AUTOSAR XML (schema 00049)
package /ComponentTypes
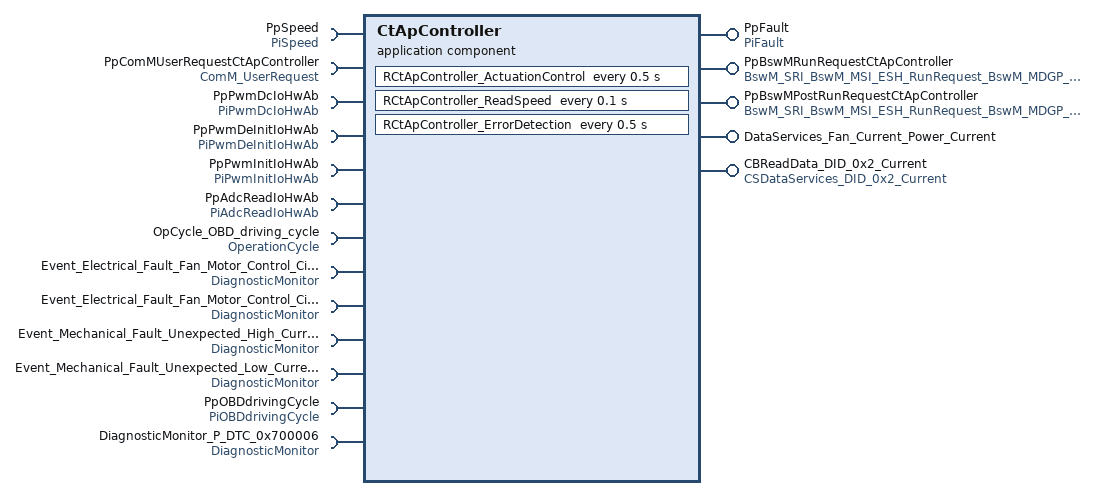
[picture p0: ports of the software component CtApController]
  application sw component type CtApController
    require port PpSpeed: nonqueued-receiver-com-spec{data-element=DeSpeed, alive-timeout=0.1, filter=data-filter-type=ALWAYS, init-value=0}, required-interface=PiSpeed
    provide port PpFault: nonqueued-sender-com-spec{data-element=DeFault, init-value=0}, provided-interface=PiFault
    require port PpComMUserRequestCtApController: required-com-specs=[RequestComMode, GetCurrentComMode, GetMaxComMode, GetRequestedComMode], required-interface=ComM_UserRequest
    provide port PpBswMRunRequestCtApController: nonqueued-sender-com-spec=requestedMode, provided-interface=BswM_SRI_BswM_MSI_ESH_RunRequest_BswM_MDGP_ESH_RunRequest
    provide port PpBswMPostRunRequestCtApController: nonqueued-sender-com-spec=requestedMode, provided-interface=BswM_SRI_BswM_MSI_ESH_RunRequest_BswM_MDGP_ESH_RunRequest
    4 x require port:
      PpPwmDcIoHwAb: client-com-spec=SetDutyCycle, required-interface=PiPwmDcIoHwAb
      PpPwmDeInitIoHwAb: client-com-spec=Pwm_DeInit, required-interface=PiPwmDeInitIoHwAb
      PpPwmInitIoHwAb: client-com-spec=Pwm_Init, required-interface=PiPwmInitIoHwAb
      PpAdcReadIoHwAb: client-com-spec=ReadGroup, required-interface=PiAdcReadIoHwAb
    provide port DataServices_Fan_Current_Power_Current: provided-com-specs=[{operation=ReadData, queue-length=1}, {operation=ConditionCheckRead, queue-length=1}], provided-interface=DataServices_Fan_Current_Power_Current
    provide port CBReadData_DID_0x2_Current: server-com-spec{operation=ReadData, queue-length=1}, provided-interface=CSDataServices_DID_0x2_Current
    7 x require port:
      OpCycle_OBD_driving_cycle: required-com-specs=[GetOperationCycleState, SetOperationCycleState], required-interface=OperationCycle
      Event_Electrical_Fault_Fan_Motor_Control_Circuit_Open: required-interface=DiagnosticMonitor
        required-com-specs:
          SetEventStatus
          ResetEventStatus
          ResetEventDebounceStatus
          GetEventUdsStatus
          GetEventStatus
          GetEventFailed
          GetEventTested
          GetDTCOfEvent
          GetFaultDetectionCounter
          GetEventFreezeFrameDataEx
          GetEventExtendedDataRecordEx
      Event_Electrical_Fault_Fan_Motor_Control_Circuit_Short: required-interface=DiagnosticMonitor
        required-com-specs:
          SetEventStatus
          ResetEventStatus
          ResetEventDebounceStatus
          GetEventUdsStatus
          GetEventStatus
          GetEventFailed
          GetEventTested
          GetDTCOfEvent
          GetFaultDetectionCounter
          GetEventFreezeFrameDataEx
          GetEventExtendedDataRecordEx
      Event_Mechanical_Fault_Unexpected_High_Current: required-interface=DiagnosticMonitor
        required-com-specs:
          SetEventStatus
          ResetEventStatus
          ResetEventDebounceStatus
          GetEventUdsStatus
          GetEventStatus
          GetEventFailed
          GetEventTested
          GetDTCOfEvent
          GetFaultDetectionCounter
          GetEventFreezeFrameDataEx
          GetEventExtendedDataRecordEx
      Event_Mechanical_Fault_Unexpected_Low_Current: required-interface=DiagnosticMonitor
        required-com-specs:
          SetEventStatus
          ResetEventStatus
          ResetEventDebounceStatus
          GetEventUdsStatus
          GetEventStatus
          GetEventFailed
          GetEventTested
          GetDTCOfEvent
          GetFaultDetectionCounter
          GetEventFreezeFrameDataEx
          GetEventExtendedDataRecordEx
      PpOBDdrivingCycle: nonqueued-receiver-com-spec{data-element=DeOBDdrivingCycle, init-value=1}, required-interface=PiOBDdrivingCycle
      DiagnosticMonitor_P_DTC_0x700006: required-interface=DiagnosticMonitor
        required-com-specs:
          GetEventExtendedDataRecordEx
          GetEventFreezeFrameDataEx
          GetFaultDetectionCounter
          GetDTCOfEvent
          GetEventTested
          GetEventFailed
          GetEventStatus
          GetEventUdsStatus
          ResetEventDebounceStatus
          ResetEventStatus
          SetEventStatus
    behavior CtApController_InternalBehavior: handle-termination-and-restart=NO-SUPPORT
      exclusive area ExArFanCurrent
      ar-typed-per-instance-memorys:
        data PimFanCurrentDid: sw-calibration-access=READ-ONLY, type=uint8
      timing event TMT_ActuationControl: start-on-event=RCtApController_ActuationControl, period=0.5
      init event CtApController_InitEvent: start-on-event=RCtApController_Init
      operation invoked event OIT_DataServices_Fan_Current_Power_Current_ConditionCheckRead_DataServices_Fan_Current_Power_Current_ConditionCheckRead: start-on-event=DataServices_Fan_Current_Power_Current_ConditionCheckRead, operation=DataServices_Fan_Current_Power_Current.ConditionCheckRead
      operation invoked event OIT_DataServices_Fan_Current_Power_Current_ReadData_DataServices_Fan_Current_Power_Current_ReadData: start-on-event=DataServices_Fan_Current_Power_Current_ReadData, operation=DataServices_Fan_Current_Power_Current.ReadData
      operation invoked event OIT_CBReadData_DID_0x2_Current_ReadData_CBReadData_DID_0x2_Current_ReadData: start-on-event=CBReadData_DID_0x2_Current_ReadData, operation=CBReadData_DID_0x2_Current.ReadData
      timing event TMT_RCtApController_ReadSpeed: start-on-event=RCtApController_ReadSpeed, period=0.1
      timing event TMT_CtApController_ErrorDetection: start-on-event=RCtApController_ErrorDetection, period=0.5
      explicit-inter-runnable-variables:
        data IrvOBDdrivingCycleOld: type=boolean, init-value=1
        data IrvActuationControl: type=Idt_Speed_PWM_Struct, init-value=fields=[Speed:0, Pwm:0, RequestedSpeed:0]
        data IrvSpeed: type=Idt_Signal_Fan_Setpoint, init-value=0
      7 x runnable:
        RCtApController_ActuationControl
          data-receive-point-by-arguments:
            access REC_PpMeasuredSpeed_DeSpeed: accessed-variable=PpSpeed.DeSpeed
            access REC_PpOBDdrivingCycle_DeOBDdrivingCycle: accessed-variable=PpOBDdrivingCycle.DeOBDdrivingCycle
          data-send-points:
            access SEND_PpHealth_DeHealth: accessed-variable=PpFault.DeFault
          read-local-variables:
            access Read_IrvOBDdrivingCycleOld: accessed-variable=IrvOBDdrivingCycleOld
            access Read_IrvSpeed: accessed-variable=IrvSpeed
          6 x sync call:
            SC_PpComMUserRequestCtApController_RequestComMode: operation=PpComMUserRequestCtApController.RequestComMode
            SC_PpPwmDcIoHwAb_SetDutyCycle: operation=PpPwmDcIoHwAb.SetDutyCycle
            SC_Event_Electrical_Fault_Fan_Motor_Control_Circuit_Open_GetEventUdsStatus: operation=Event_Electrical_Fault_Fan_Motor_Control_Circuit_Open.GetEventUdsStatus
            SC_Event_Electrical_Fault_Fan_Motor_Control_Circuit_Short_GetEventUdsStatus: operation=Event_Electrical_Fault_Fan_Motor_Control_Circuit_Short.GetEventUdsStatus
            SC_Event_Mechanical_Fault_Unexpected_High_Current_GetEventUdsStatus: operation=Event_Mechanical_Fault_Unexpected_High_Current.GetEventUdsStatus
            SC_Event_Mechanical_Fault_Unexpected_Low_Current_GetEventUdsStatus: operation=Event_Mechanical_Fault_Unexpected_Low_Current.GetEventUdsStatus
          written-local-variables:
            access WRITE_IrvOBDdrivingCycleOld: accessed-variable=IrvOBDdrivingCycleOld
            access WRITE_IrvActuationSpeed: accessed-variable=IrvActuationControl
        RCtApController_Init
          data-send-points:
            access SEND_PpBswMPostRunRequestCtApController_requestedMode: accessed-variable=PpBswMPostRunRequestCtApController.requestedMode
            access SEND_PpBswMRunRequestCtApController_requestedMode: accessed-variable=PpBswMRunRequestCtApController.requestedMode
          read-local-variables:
            access Read_IrvOBDdrivingCycleOld: accessed-variable=IrvOBDdrivingCycleOld
          sync call SC_PpComMUserRequestCtApController_RequestComMode: operation=PpComMUserRequestCtApController.RequestComMode
          sync call SC_OpCycle_OBD_driving_cycle_SetOperationCycleState: operation=OpCycle_OBD_driving_cycle.SetOperationCycleState
          written-local-variables:
            access WRITE_IrvOBDdrivingCycleOld: accessed-variable=IrvOBDdrivingCycleOld
        DataServices_Fan_Current_Power_Current_ConditionCheckRead: can-enter-exclusive-area=ExArFanCurrent
        DataServices_Fan_Current_Power_Current_ReadData: can-enter-exclusive-area=ExArFanCurrent
        CBReadData_DID_0x2_Current_ReadData
        RCtApController_ErrorDetection
          data-send-points:
            access SEND_PpFault_DeFault: accessed-variable=PpFault.DeFault
          read-local-variables:
            access Read_IrvActuationSpeed: accessed-variable=IrvActuationControl
          6 x sync call:
            SC_Event_Electrical_Fault_Fan_Motor_Control_Circuit_Open_SetEventStatus: operation=Event_Electrical_Fault_Fan_Motor_Control_Circuit_Open.SetEventStatus
            SC_Event_Electrical_Fault_Fan_Motor_Control_Circuit_Short_SetEventStatus: operation=Event_Electrical_Fault_Fan_Motor_Control_Circuit_Short.SetEventStatus
            SC_Event_Mechanical_Fault_Unexpected_High_Current_SetEventStatus: operation=Event_Mechanical_Fault_Unexpected_High_Current.SetEventStatus
            SC_Event_Mechanical_Fault_Unexpected_Low_Current_SetEventStatus: operation=Event_Mechanical_Fault_Unexpected_Low_Current.SetEventStatus
            SC_PpComMUserRequestCtApController_RequestComMode: operation=PpComMUserRequestCtApController.RequestComMode
            AC_PpAdcReadIoHwAb_ReadGroup: operation=PpAdcReadIoHwAb.ReadGroup
        RCtApController_ReadSpeed
          data-receive-point-by-arguments:
            access REC_PpOBDdrivingCycle_DeOBDdrivingCycle: accessed-variable=PpOBDdrivingCycle.DeOBDdrivingCycle
            access REC_PpSpeed_DeSpeed: accessed-variable=PpSpeed.DeSpeed
          data-send-points:
            access SEND_PpFault_DeFault: accessed-variable=PpFault.DeFault
          read-local-variables:
            access Read_IrvOBDdrivingCycleOld: accessed-variable=IrvOBDdrivingCycleOld
          sync call SC_PpComMUserRequestCtApController_RequestComMode: operation=PpComMUserRequestCtApController.RequestComMode
          sync call SC_DiagnosticMonitor_P_DTC_0x700001_SetEventStatus: operation=DiagnosticMonitor_P_DTC_0x700006.SetEventStatus
          written-local-variables:
            access WRITE_IrvOBDdrivingCycleOld: accessed-variable=IrvOBDdrivingCycleOld
            access WRITE_IrvSpeed: accessed-variable=IrvSpeed
      swc service dependency SnNvMPimFanCurrentDid: category=SERVICE, assigned-datas=role-based-data-assignment={role=ramBlock, used-data-element=PimFanCurrentDid}
        service-needs:
          nv block needs SnNvMPimFanCurrentDid: n-data-sets=0, ram-block-status-control=API, readonly=false, reliability=NO-PROTECTION, resistant-to-changed-sw=false, restore-at-start=true, store-at-shutdown=true, write-only-once=false
      swc service dependency DiagnosticEventNeed_B_DTC_SPEEDOOR_0x700006: assigned-ports=role-based-port-assignment={port-prototype=DiagnosticMonitor_P_DTC_0x700006, role=DiagnosticMonitor}
        service-needs:
          diagnostic event needs DiagnosticEventNeed_B_DTC_SPEEDOOR_0x700006: uds-dtc-number=1
  swc implementation CtApController_Implementation: behavior=CtApController_InternalBehavior
